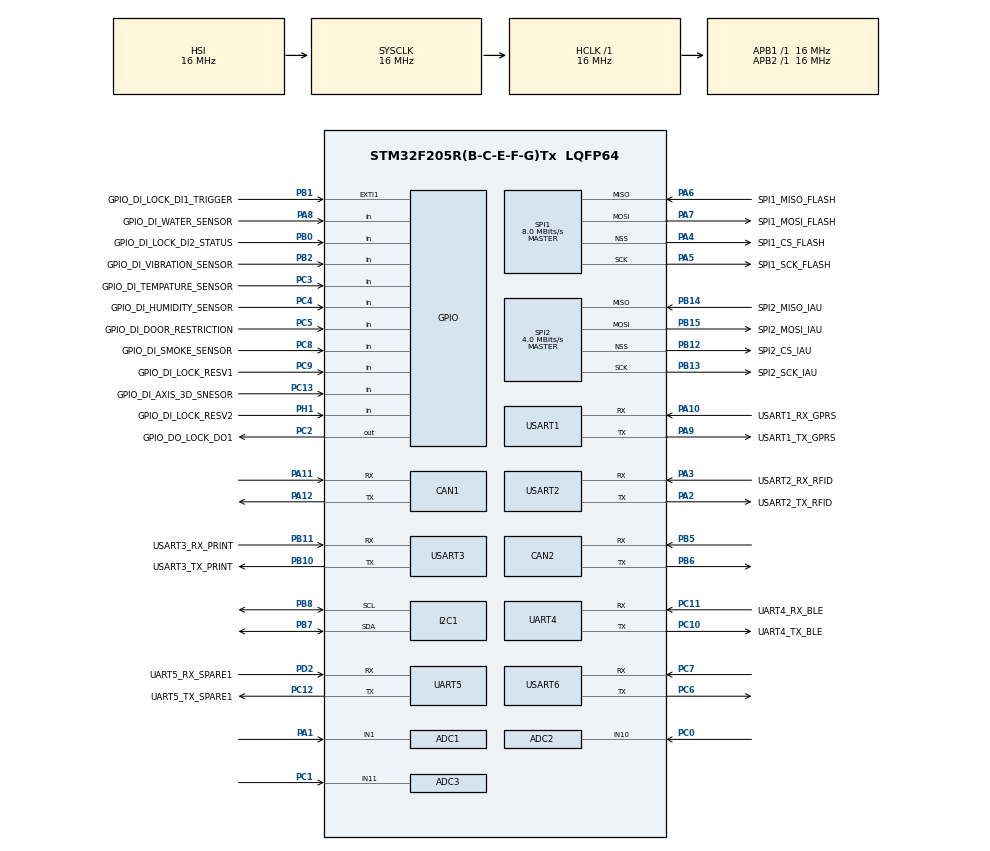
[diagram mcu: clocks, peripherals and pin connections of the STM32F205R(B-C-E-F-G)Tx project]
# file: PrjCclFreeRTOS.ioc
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ADC1.Channel-4\#ChannelRegularConversion=ADC_CHANNEL_1
ADC1.NbrOfConversionFlag=1
ADC1.Rank-4\#ChannelRegularConversion=1
ADC1.SamplingTime-4\#ChannelRegularConversion=ADC_SAMPLETIME_3CYCLES
ADC1.master=1
ADC2.Channel-0\#ChannelRegularConversion=ADC_CHANNEL_10
ADC2.NbrOfConversionFlag=1
ADC2.Rank-0\#ChannelRegularConversion=1
ADC2.SamplingTime-0\#ChannelRegularConversion=ADC_SAMPLETIME_3CYCLES
ADC3.Channel-147\#ChannelRegularConversion=ADC_CHANNEL_11
ADC3.NbrOfConversionFlag=1
ADC3.Rank-147\#ChannelRegularConversion=1
ADC3.SamplingTime-147\#ChannelRegularConversion=ADC_SAMPLETIME_3CYCLES
CAN1.BS1=CAN_BS1_1TQ
CAN1.BS2=CAN_BS2_1TQ
CAN1.CalculateTimeBit=3000
CAN1.CalculateTimeQuantum=1000.0
CAN2.BS1=CAN_BS1_1TQ
CAN2.BS2=CAN_BS2_1TQ
CAN2.CalculateTimeBit=3000
CAN2.CalculateTimeQuantum=1000.0
Dma.Request0=SPI1_TX
Dma.Request1=SPI1_RX
Dma.SPI1_RX.1.Direction=DMA_PERIPH_TO_MEMORY
Dma.SPI1_RX.1.FIFOMode=DMA_FIFOMODE_DISABLE
Dma.SPI1_RX.1.Instance=DMA2_Stream0
Dma.SPI1_RX.1.MemDataAlignment=DMA_MDATAALIGN_BYTE
Dma.SPI1_RX.1.MemInc=DMA_MINC_ENABLE
Dma.SPI1_RX.1.Mode=DMA_NORMAL
Dma.SPI1_RX.1.PeriphDataAlignment=DMA_PDATAALIGN_BYTE
Dma.SPI1_RX.1.PeriphInc=DMA_PINC_DISABLE
Dma.SPI1_RX.1.Priority=DMA_PRIORITY_MEDIUM
Dma.SPI1_TX.0.Direction=DMA_MEMORY_TO_PERIPH
Dma.SPI1_TX.0.FIFOMode=DMA_FIFOMODE_DISABLE
Dma.SPI1_TX.0.Instance=DMA2_Stream3
Dma.SPI1_TX.0.MemDataAlignment=DMA_MDATAALIGN_BYTE
Dma.SPI1_TX.0.MemInc=DMA_MINC_ENABLE
Dma.SPI1_TX.0.Mode=DMA_NORMAL
Dma.SPI1_TX.0.PeriphDataAlignment=DMA_PDATAALIGN_BYTE
Dma.SPI1_TX.0.PeriphInc=DMA_PINC_DISABLE
Dma.SPI1_TX.0.Priority=DMA_PRIORITY_MEDIUM
FREERTOS.INCLUDE_eTaskGetState=1
FREERTOS.INCLUDE_pcTaskGetTaskName=1
FREERTOS.Queues01=myQueue01,16,uint16_t,NULL
FREERTOS.Tasks01=defaultTask,0,128,StartDefaultTask,Default;myTask02,0,128,StartTask02,Default
FREERTOS.Timers01=myTimer01,Callback01,osTimerPeriodic,Default
FREERTOS.configUSE_TICKLESS_IDLE=1
FREERTOS.configUSE_TIMERS=1
Mcu.Family=STM32F2
Mcu.Name=STM32F205R(B-C-E-F-G)Tx
Mcu.Package=LQFP64
NVIC.CAN1_RX0_IRQn=true\:5\:0\:false\:true\:true\:1\:true
NVIC.CAN1_RX1_IRQn=true\:5\:0\:false\:true\:true\:2\:true
NVIC.CAN2_RX0_IRQn=true\:5\:0\:false\:true\:true\:13\:true
NVIC.CAN2_RX1_IRQn=true\:5\:0\:false\:true\:true\:14\:true
NVIC.DMA2_Stream0_IRQn=true\:0\:0\:false\:true\:true\:11\:false
NVIC.DMA2_Stream3_IRQn=true\:0\:0\:false\:true\:true\:12\:false
NVIC.HASH_RNG_IRQn=true\:0\:0\:false\:false\:true\:false
NVIC.I2C1_ER_IRQn=true\:0\:0\:false\:true\:true\:4\:false
NVIC.I2C1_EV_IRQn=true\:0\:0\:false\:true\:true\:3\:false
NVIC.PriorityGroup=NVIC_PRIORITYGROUP_4
NVIC.RTC_Alarm_IRQn=true\:5\:0\:false\:false\:true\:true
NVIC.RTC_WKUP_IRQn=true\:5\:0\:false\:false\:true\:true
NVIC.SPI2_IRQn=true\:5\:0\:false\:true\:true\:5\:true
NVIC.TIM1_UP_TIM10_IRQn=true\:0\:0\:false\:false\:true\:false
NVIC.TIM6_DAC_IRQn=true\:0\:0\:false\:false\:true\:false
NVIC.TIM7_IRQn=true\:0\:0\:false\:false\:true\:false
NVIC.TimeBase=TIM1_UP_TIM10_IRQn
NVIC.TimeBaseIP=TIM1
NVIC.UART4_IRQn=true\:5\:0\:false\:true\:true\:9\:true
NVIC.UART5_IRQn=true\:5\:0\:false\:true\:true\:10\:true
NVIC.USART1_IRQn=true\:5\:0\:false\:true\:true\:6\:true
NVIC.USART2_IRQn=true\:5\:0\:false\:true\:true\:7\:true
NVIC.USART3_IRQn=true\:5\:0\:false\:true\:true\:8\:true
NVIC.USART6_IRQn=true\:0\:0\:false\:true\:true\:15\:false
NVIC.WWDG_IRQn=true\:0\:0\:false\:false\:true\:false
PA0-WKUP.Mode=SYS_WakeUp0
PA0-WKUP.Signal=SYS_WKUP
PA1.Signal=ADCx_IN1
PA10.GPIO_Label=USART1_RX_GPRS
PA10.Mode=Asynchronous
PA10.Signal=USART1_RX
PA11.Mode=Master
PA11.Signal=CAN1_RX
PA12.Mode=Master
PA12.Signal=CAN1_TX
PA13.Mode=JTAG_5_pins
PA13.Signal=SYS_JTMS-SWDIO
PA14.Mode=JTAG_5_pins
PA14.Signal=SYS_JTCK-SWCLK
PA15.Mode=JTAG_5_pins
PA15.Signal=SYS_JTDI
PA2.GPIO_Label=USART2_TX_RFID
PA2.Mode=Asynchronous
PA2.Signal=USART2_TX
PA3.GPIO_Label=USART2_RX_RFID
PA3.Mode=Asynchronous
PA3.Signal=USART2_RX
PA4.GPIO_Label=SPI1_CS_FLASH
PA4.Mode=NSS_Signal_Hard_Output
PA4.Signal=SPI1_NSS
PA5.GPIO_Label=SPI1_SCK_FLASH
PA5.Mode=Full_Duplex_Master
PA5.Signal=SPI1_SCK
PA6.GPIO_Label=SPI1_MISO_FLASH
PA6.Mode=Full_Duplex_Master
PA6.Signal=SPI1_MISO
PA7.GPIO_Label=SPI1_MOSI_FLASH
PA7.Mode=Full_Duplex_Master
PA7.Signal=SPI1_MOSI
PA8.GPIO_Label=GPIO_DI_WATER_SENSOR
PA8.Signal=GPIO_Input
PA9.GPIO_Label=USART1_TX_GPRS
PA9.Mode=Asynchronous
PA9.Signal=USART1_TX
PB0.GPIO_Label=GPIO_DI_LOCK_DI2_STATUS
PB0.Signal=GPIO_Input
PB1.GPIO_Label=GPIO_DI_LOCK_DI1_TRIGGER
PB1.Signal=GPXTI1
PB10.GPIO_Label=USART3_TX_PRINT
PB10.Mode=Asynchronous
PB10.Signal=USART3_TX
PB11.GPIO_Label=USART3_RX_PRINT
PB11.Mode=Asynchronous
PB11.Signal=USART3_RX
PB12.GPIO_Label=SPI2_CS_IAU
PB12.Mode=NSS_Signal_Hard_Output
PB12.Signal=SPI2_NSS
PB13.GPIO_Label=SPI2_SCK_IAU
PB13.Mode=Full_Duplex_Master
PB13.Signal=SPI2_SCK
PB14.GPIO_Label=SPI2_MISO_IAU
PB14.Mode=Full_Duplex_Master
PB14.Signal=SPI2_MISO
PB15.GPIO_Label=SPI2_MOSI_IAU
PB15.Mode=Full_Duplex_Master
PB15.Signal=SPI2_MOSI
PB2.GPIO_Label=GPIO_DI_VIBRATION_SENSOR
PB2.Signal=GPIO_Input
PB3.Mode=JTAG_5_pins
PB3.Signal=SYS_JTDO-SWO
PB4.Mode=JTAG_5_pins
PB4.Signal=SYS_JTRST
PB5.Mode=Slave
PB5.Signal=CAN2_RX
PB6.Mode=Slave
PB6.Signal=CAN2_TX
PB7.Mode=I2C
PB7.Signal=I2C1_SDA
PB8.Mode=I2C
PB8.Signal=I2C1_SCL
PC0.Signal=ADCx_IN10
PC1.Signal=ADCx_IN11
PC10.GPIO_Label=UART4_TX_BLE
PC10.Mode=Asynchronous
PC10.Signal=UART4_TX
PC11.GPIO_Label=UART4_RX_BLE
PC11.Mode=Asynchronous
PC11.Signal=UART4_RX
PC12.GPIO_Label=UART5_TX_SPARE1
PC12.Mode=Asynchronous
PC12.Signal=UART5_TX
PC13.GPIO_Label=GPIO_DI_AXIS_3D_SNESOR
PC13.Signal=GPIO_Input
PC14-OSC32_IN.Mode=LSE-External-Oscillator
PC14-OSC32_IN.Signal=RCC_OSC32_IN
PC15-OSC32_OUT.Mode=LSE-External-Oscillator
PC15-OSC32_OUT.Signal=RCC_OSC32_OUT
PC2.GPIO_Label=GPIO_DO_LOCK_DO1
PC2.Signal=GPIO_Output
PC3.GPIO_Label=GPIO_DI_TEMPATURE_SENSOR
PC3.Signal=GPIO_Input
PC4.GPIO_Label=GPIO_DI_HUMIDITY_SENSOR
PC4.Signal=GPIO_Input
PC5.GPIO_Label=GPIO_DI_DOOR_RESTRICTION
PC5.Signal=GPIO_Input
PC6.Mode=Asynchronous
PC6.Signal=USART6_TX
PC7.Mode=Asynchronous
PC7.Signal=USART6_RX
PC8.GPIO_Label=GPIO_DI_SMOKE_SENSOR
PC8.Signal=GPIO_Input
PC9.GPIO_Label=GPIO_DI_LOCK_RESV1
PC9.Signal=GPIO_Input
PD2.GPIO_Label=UART5_RX_SPARE1
PD2.Mode=Asynchronous
PD2.Signal=UART5_RX
PH1-OSC_OUT.GPIO_Label=GPIO_DI_LOCK_RESV2
PH1-OSC_OUT.Signal=GPIO_Input
ProjectManager.HeapSize=0x200
ProjectManager.StackSize=0x400
ProjectManager.TargetToolchain=MDK-ARM V5
RCC.48MHZClocksFreq_Value=48000000
RCC.AHBFreq_Value=16000000
RCC.APB1Freq_Value=16000000
RCC.APB1TimFreq_Value=16000000
RCC.APB2Freq_Value=16000000
RCC.APB2TimFreq_Value=16000000
RCC.CortexFreq_Value=16000000
RCC.HCLKFreq_Value=16000000
RCC.HSE_VALUE=25000000
RCC.HSI_VALUE=16000000
RCC.SYSCLKFreq_VALUE=16000000
RCC.VCOOutputFreq_Value=192000000
RTC.Date=2
RTC.Hours_A-Alarm\ A=1
RTC.Hours_B-Alarm\ B=2
RTC.Month=RTC_MONTH_APRIL
RTC.Year=14
SH.ADCx_IN1.0=ADC1_IN1,IN1
SH.ADCx_IN10.0=ADC2_IN10,IN10
SH.ADCx_IN11.0=ADC3_IN11,IN11
SPI1.BaudRatePrescaler=SPI_BAUDRATEPRESCALER_2
SPI1.CalculateBaudRate=8.0 MBits/s
SPI1.Mode=SPI_MODE_MASTER
SPI1.VirtualNSS=VM_NSSHARD
SPI2.BaudRatePrescaler=SPI_BAUDRATEPRESCALER_4
SPI2.CalculateBaudRate=4.0 MBits/s
SPI2.Mode=SPI_MODE_MASTER
SPI2.VirtualNSS=VM_NSSHARD
VP_FREERTOS_VS_ENABLE.Mode=Enabled
VP_IWDG_VS_IWDG.Mode=IWDG_Activate
VP_RNG_VS_RNG.Mode=RNG_Activate
VP_RTC_VS_RTC_Activate.Mode=RTC_Enabled
VP_RTC_VS_RTC_Alarm_A_Intern.Mode=Alarm A
VP_RTC_VS_RTC_Alarm_B_Intern.Mode=Alarm B
VP_RTC_VS_RTC_Calendar.Mode=RTC_Calendar
VP_RTC_VS_RTC_WakeUp_intern.Mode=WakeUp
VP_SYS_VS_tim1.Mode=TIM1
VP_TIM6_VS_ClockSourceINT.Mode=Enable_Timer
VP_TIM7_VS_ClockSourceINT.Mode=Enable_Timer
VP_WWDG_VS_WWDG.Mode=WWDG_Activate
board=PrjCclFreeRTOS

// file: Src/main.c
/**
  ******************************************************************************
  * File Name          : main.c
  * Description        : Main program body
  ******************************************************************************
  *
  * Copyright (c) 2016 STMicroelectronics International N.V.
  * All rights reserved.
  *
  * Redistribution and use in source and binary forms, with or without
  * modification, are permitted, provided that the following conditions are met:
  *
  * 1. Redistribution of source code must retain the above copyright notice,
  *    this list of conditions and the following disclaimer.
  * 2. Redistributions in binary form must reproduce the above copyright notice,
  *    this list of conditions and the following disclaimer in the documentation
  *    and/or other materials provided with the distribution.
  * 3. Neither the name of STMicroelectronics nor the names of other
  *    contributors to this software may be used to endorse or promote products
  *    derived from this software without specific written permission.
  * 4. This software, including modifications and/or derivative works of this
  *    software, must execute solely and exclusively on microcontroller or
  *    microprocessor devices manufactured by or for STMicroelectronics.
  * 5. Redistribution and use of this software other than as permitted under
  *    this license is void and will automatically terminate your rights under
  *    this license.
  *
  * THIS SOFTWARE IS PROVIDED BY STMICROELECTRONICS AND CONTRIBUTORS "AS IS"
  * AND ANY EXPRESS, IMPLIED OR STATUTORY WARRANTIES, INCLUDING, BUT NOT
  * LIMITED TO, THE IMPLIED WARRANTIES OF MERCHANTABILITY, FITNESS FOR A
  * PARTICULAR PURPOSE AND NON-INFRINGEMENT OF THIRD PARTY INTELLECTUAL PROPERTY
  * RIGHTS ARE DISCLAIMED TO THE FULLEST EXTENT PERMITTED BY LAW. IN NO EVENT
  * SHALL STMICROELECTRONICS OR CONTRIBUTORS BE LIABLE FOR ANY DIRECT, INDIRECT,
  * INCIDENTAL, SPECIAL, EXEMPLARY, OR CONSEQUENTIAL DAMAGES (INCLUDING, BUT NOT
  * LIMITED TO, PROCUREMENT OF SUBSTITUTE GOODS OR SERVICES; LOSS OF USE, DATA,
  * OR PROFITS; OR BUSINESS INTERRUPTION) HOWEVER CAUSED AND ON ANY THEORY OF
  * LIABILITY, WHETHER IN CONTRACT, STRICT LIABILITY, OR TORT (INCLUDING
  * NEGLIGENCE OR OTHERWISE) ARISING IN ANY WAY OUT OF THE USE OF THIS SOFTWARE,
  * EVEN IF ADVISED OF THE POSSIBILITY OF SUCH DAMAGE.
  *
  ******************************************************************************
  */
#include "main.h"
#include "stm32f2xx_hal.h"
#include "cmsis_os.h"
#include "adc.h"
#include "can.h"
#include "dma.h"
#include "i2c.h"
#include "iwdg.h"
#include "rng.h"
#include "rtc.h"
#include "spi.h"
#include "tim.h"
#include "usart.h"
#include "wwdg.h"
#include "gpio.h"

/* USER CODE BEGIN PV */
/* Private variables ---------------------------------------------------------*/

/* USER CODE END PV */

void SystemClock_Config(void);
void Error_Handler(void);
void MX_FREERTOS_Init(void);
static void MX_NVIC_Init(void);

/* USER CODE BEGIN PFP */
/* Private function prototypes -----------------------------------------------*/

/* USER CODE END PFP */

int main(void)
{

  /* MCU Configuration----------------------------------------------------------*/

  /* Reset of all peripherals, Initializes the Flash interface and the Systick. */
  HAL_Init();

  /* Configure the system clock */
  SystemClock_Config();

  /* Initialize all configured peripherals */
  MX_GPIO_Init();
  MX_DMA_Init();
  MX_UART4_Init();
  MX_UART5_Init();
  MX_USART1_UART_Init();
  MX_CAN1_Init();
  MX_CAN2_Init();
  MX_IWDG_Init();
  MX_RTC_Init();
  MX_SPI1_Init();
  MX_SPI2_Init();
  MX_USART2_UART_Init();
  MX_USART3_UART_Init();
  MX_ADC1_Init();
  MX_I2C1_Init();
  MX_RNG_Init();
  MX_ADC2_Init();
  MX_ADC3_Init();
  MX_TIM6_Init();
  MX_TIM7_Init();
  MX_USART6_UART_Init();
  MX_WWDG_Init();

  /* Initialize interrupts */
  MX_NVIC_Init();

  /* Call init function for freertos objects (in freertos.c) */
  MX_FREERTOS_Init();

  /* Start scheduler */
  osKernelStart();

  /* We should never get here as control is now taken by the scheduler */

  /* Infinite loop */
  while (1)
  {

  }

}

/** System Clock Configuration
*/
void SystemClock_Config(void)
{

  RCC_OscInitTypeDef RCC_OscInitStruct;
  RCC_ClkInitTypeDef RCC_ClkInitStruct;
  RCC_PeriphCLKInitTypeDef PeriphClkInitStruct;

    /**Initializes the CPU, AHB and APB busses clocks
    */
  RCC_OscInitStruct.OscillatorType = RCC_OSCILLATORTYPE_HSI|RCC_OSCILLATORTYPE_LSI;
  RCC_OscInitStruct.HSIState = RCC_HSI_ON;
  RCC_OscInitStruct.HSICalibrationValue = 16;
  RCC_OscInitStruct.LSIState = RCC_LSI_ON;
  RCC_OscInitStruct.PLL.PLLState = RCC_PLL_ON;
  RCC_OscInitStruct.PLL.PLLSource = RCC_PLLSOURCE_HSI;
  RCC_OscInitStruct.PLL.PLLM = 16;
  RCC_OscInitStruct.PLL.PLLN = 192;
  RCC_OscInitStruct.PLL.PLLP = RCC_PLLP_DIV2;
  RCC_OscInitStruct.PLL.PLLQ = 4;
  if (HAL_RCC_OscConfig(&RCC_OscInitStruct) != HAL_OK)
  {
    Error_Handler();
  }

    /**Initializes the CPU, AHB and APB busses clocks
    */
  RCC_ClkInitStruct.ClockType = RCC_CLOCKTYPE_HCLK|RCC_CLOCKTYPE_SYSCLK
                              |RCC_CLOCKTYPE_PCLK1|RCC_CLOCKTYPE_PCLK2;
  RCC_ClkInitStruct.SYSCLKSource = RCC_SYSCLKSOURCE_HSI;
  RCC_ClkInitStruct.AHBCLKDivider = RCC_SYSCLK_DIV1;
  RCC_ClkInitStruct.APB1CLKDivider = RCC_HCLK_DIV1;
  RCC_ClkInitStruct.APB2CLKDivider = RCC_HCLK_DIV1;

  if (HAL_RCC_ClockConfig(&RCC_ClkInitStruct, FLASH_LATENCY_0) != HAL_OK)
  {
    Error_Handler();
  }

  PeriphClkInitStruct.PeriphClockSelection = RCC_PERIPHCLK_RTC;
  PeriphClkInitStruct.RTCClockSelection = RCC_RTCCLKSOURCE_LSI;
  if (HAL_RCCEx_PeriphCLKConfig(&PeriphClkInitStruct) != HAL_OK)
  {
    Error_Handler();
  }

    /**Configure the Systick interrupt time
    */
  HAL_SYSTICK_Config(HAL_RCC_GetHCLKFreq()/1000);

    /**Configure the Systick
    */
  HAL_SYSTICK_CLKSourceConfig(SYSTICK_CLKSOURCE_HCLK);

  /* SysTick_IRQn interrupt configuration */
  HAL_NVIC_SetPriority(SysTick_IRQn, 15, 0);
}

/** NVIC Configuration
*/
static void MX_NVIC_Init(void)
{
  /* CAN1_RX0_IRQn interrupt configuration */
  HAL_NVIC_SetPriority(CAN1_RX0_IRQn, 5, 0);
  HAL_NVIC_EnableIRQ(CAN1_RX0_IRQn);
  /* CAN1_RX1_IRQn interrupt configuration */
  HAL_NVIC_SetPriority(CAN1_RX1_IRQn, 5, 0);
  HAL_NVIC_EnableIRQ(CAN1_RX1_IRQn);
  /* I2C1_EV_IRQn interrupt configuration */
  HAL_NVIC_SetPriority(I2C1_EV_IRQn, 0, 0);
  HAL_NVIC_EnableIRQ(I2C1_EV_IRQn);
  /* I2C1_ER_IRQn interrupt configuration */
  HAL_NVIC_SetPriority(I2C1_ER_IRQn, 0, 0);
  HAL_NVIC_EnableIRQ(I2C1_ER_IRQn);
  /* SPI2_IRQn interrupt configuration */
  HAL_NVIC_SetPriority(SPI2_IRQn, 5, 0);
  HAL_NVIC_EnableIRQ(SPI2_IRQn);
  /* USART1_IRQn interrupt configuration */
  HAL_NVIC_SetPriority(USART1_IRQn, 5, 0);
  HAL_NVIC_EnableIRQ(USART1_IRQn);
  /* USART2_IRQn interrupt configuration */
  HAL_NVIC_SetPriority(USART2_IRQn, 5, 0);
  HAL_NVIC_EnableIRQ(USART2_IRQn);
  /* USART3_IRQn interrupt configuration */
  HAL_NVIC_SetPriority(USART3_IRQn, 5, 0);
  HAL_NVIC_EnableIRQ(USART3_IRQn);
  /* UART4_IRQn interrupt configuration */
  HAL_NVIC_SetPriority(UART4_IRQn, 5, 0);
  HAL_NVIC_EnableIRQ(UART4_IRQn);
  /* UART5_IRQn interrupt configuration */
  HAL_NVIC_SetPriority(UART5_IRQn, 5, 0);
  HAL_NVIC_EnableIRQ(UART5_IRQn);
  /* DMA2_Stream0_IRQn interrupt configuration */
  HAL_NVIC_SetPriority(DMA2_Stream0_IRQn, 0, 0);
  HAL_NVIC_EnableIRQ(DMA2_Stream0_IRQn);
  /* DMA2_Stream3_IRQn interrupt configuration */
  HAL_NVIC_SetPriority(DMA2_Stream3_IRQn, 0, 0);
  HAL_NVIC_EnableIRQ(DMA2_Stream3_IRQn);
  /* CAN2_RX0_IRQn interrupt configuration */
  HAL_NVIC_SetPriority(CAN2_RX0_IRQn, 5, 0);
  HAL_NVIC_EnableIRQ(CAN2_RX0_IRQn);
  /* CAN2_RX1_IRQn interrupt configuration */
  HAL_NVIC_SetPriority(CAN2_RX1_IRQn, 5, 0);
  HAL_NVIC_EnableIRQ(CAN2_RX1_IRQn);
  /* USART6_IRQn interrupt configuration */
  HAL_NVIC_SetPriority(USART6_IRQn, 0, 0);
  HAL_NVIC_EnableIRQ(USART6_IRQn);
}

void HAL_TIM_PeriodElapsedCallback(TIM_HandleTypeDef *htim)
{
  if (htim->Instance == TIM1) {
    HAL_IncTick();
  }
}

void Error_Handler(void)
{
  while(1)
  {
  }
}

/************************ (C) COPYRIGHT STMicroelectronics *****END OF FILE****/

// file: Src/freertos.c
/**
  ******************************************************************************
  * File Name          : freertos.c
  * Description        : Code for freertos applications
  ******************************************************************************
  *
  * Copyright (c) 2016 STMicroelectronics International N.V.
  * All rights reserved.
  *
  * Redistribution and use in source and binary forms, with or without
  * modification, are permitted, provided that the following conditions are met:
  *
  * 1. Redistribution of source code must retain the above copyright notice,
  *    this list of conditions and the following disclaimer.
  * 2. Redistributions in binary form must reproduce the above copyright notice,
  *    this list of conditions and the following disclaimer in the documentation
  *    and/or other materials provided with the distribution.
  * 3. Neither the name of STMicroelectronics nor the names of other
  *    contributors to this software may be used to endorse or promote products
  *    derived from this software without specific written permission.
  * 4. This software, including modifications and/or derivative works of this
  *    software, must execute solely and exclusively on microcontroller or
  *    microprocessor devices manufactured by or for STMicroelectronics.
  * 5. Redistribution and use of this software other than as permitted under
  *    this license is void and will automatically terminate your rights under
  *    this license.
  *
  * THIS SOFTWARE IS PROVIDED BY STMICROELECTRONICS AND CONTRIBUTORS "AS IS"
  * AND ANY EXPRESS, IMPLIED OR STATUTORY WARRANTIES, INCLUDING, BUT NOT
  * LIMITED TO, THE IMPLIED WARRANTIES OF MERCHANTABILITY, FITNESS FOR A
  * PARTICULAR PURPOSE AND NON-INFRINGEMENT OF THIRD PARTY INTELLECTUAL PROPERTY
  * RIGHTS ARE DISCLAIMED TO THE FULLEST EXTENT PERMITTED BY LAW. IN NO EVENT
  * SHALL STMICROELECTRONICS OR CONTRIBUTORS BE LIABLE FOR ANY DIRECT, INDIRECT,
  * INCIDENTAL, SPECIAL, EXEMPLARY, OR CONSEQUENTIAL DAMAGES (INCLUDING, BUT NOT
  * LIMITED TO, PROCUREMENT OF SUBSTITUTE GOODS OR SERVICES; LOSS OF USE, DATA,
  * OR PROFITS; OR BUSINESS INTERRUPTION) HOWEVER CAUSED AND ON ANY THEORY OF
  * LIABILITY, WHETHER IN CONTRACT, STRICT LIABILITY, OR TORT (INCLUDING
  * NEGLIGENCE OR OTHERWISE) ARISING IN ANY WAY OUT OF THE USE OF THIS SOFTWARE,
  * EVEN IF ADVISED OF THE POSSIBILITY OF SUCH DAMAGE.
  *
  ******************************************************************************
  */

#include "FreeRTOS.h"
#include "task.h"
#include "cmsis_os.h"

osThreadId defaultTaskHandle;
osThreadId myTask02Handle;
osMessageQId myQueue01Handle;
osTimerId myTimer01Handle;

void StartDefaultTask(void const * argument);
void StartTask02(void const * argument);
void Callback01(void const * argument);

void MX_FREERTOS_Init(void); /* (MISRA C 2004 rule 8.1) */

/* Pre/Post sleep processing prototypes */
void PreSleepProcessing(uint32_t *ulExpectedIdleTime);
void PostSleepProcessing(uint32_t *ulExpectedIdleTime);

/* Hook prototypes */

/* USER CODE BEGIN PREPOSTSLEEP */
void PreSleepProcessing(uint32_t *ulExpectedIdleTime)
{
/* place for user code */
}

void PostSleepProcessing(uint32_t *ulExpectedIdleTime)
{
/* place for user code */
}
/* USER CODE END PREPOSTSLEEP */

/* Init FreeRTOS */

void MX_FREERTOS_Init(void) {

  /* Create the timer(s) */
  /* definition and creation of myTimer01 */
  osTimerDef(myTimer01, Callback01);
  myTimer01Handle = osTimerCreate(osTimer(myTimer01), osTimerPeriodic, NULL);

  /* Create the thread(s) */
  /* definition and creation of defaultTask */
  osThreadDef(defaultTask, StartDefaultTask, osPriorityNormal, 0, 128);
  defaultTaskHandle = osThreadCreate(osThread(defaultTask), NULL);

  /* definition and creation of myTask02 */
  osThreadDef(myTask02, StartTask02, osPriorityNormal, 0, 128);
  myTask02Handle = osThreadCreate(osThread(myTask02), NULL);

  /* Create the queue(s) */
  /* definition and creation of myQueue01 */
  osMessageQDef(myQueue01, 16, uint16_t);
  myQueue01Handle = osMessageCreate(osMessageQ(myQueue01), NULL);

}

/* StartDefaultTask function */
void StartDefaultTask(void const * argument)
{

  for(;;)
  {
    osDelay(1);
  }
}

/* StartTask02 function */
void StartTask02(void const * argument)
{
  for(;;)
  {
    osDelay(1);
  }
}

/* Callback01 function */
void Callback01(void const * argument)
{
}

/************************ (C) COPYRIGHT STMicroelectronics *****END OF FILE****/
